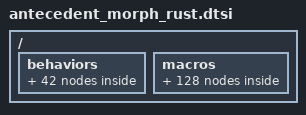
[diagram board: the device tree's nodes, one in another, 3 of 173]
// Rust schema version v1.2
// Automatically generated by Antecedent Morph Configurator

/ {
    behaviors {
        // Mod-Morphs
        // Base layer
        // NE
        amrsneagm: amrsneagm {
            compatible = "zmk,behavior-mod-morph";
            #binding-cells = <0>;
            bindings = <&amrsnea>, <&amrsneg>;
            mods = <(MOD_LGUI)>;
        };
        amrsnecagm: amrsnecagm {
            compatible = "zmk,behavior-mod-morph";
            #binding-cells = <0>;
            bindings = <&amrsnec>, <&amrsneagm>;
            mods = <(MOD_LALT|MOD_LGUI)>;
        };
        amrsnem: amrsnem {
            compatible = "zmk,behavior-mod-morph";
            #binding-cells = <0>;
            bindings = <&amrsne>, <&amrsnecagm>;
            mods = <(MOD_LCTL|MOD_LALT|MOD_LGUI)>;
        };
        // E
        amrseagm: amrseagm {
            compatible = "zmk,behavior-mod-morph";
            #binding-cells = <0>;
            bindings = <&amrsea>, <&amrseg>;
            mods = <(MOD_LGUI)>;
        };
        amrsecagm: amrsecagm {
            compatible = "zmk,behavior-mod-morph";
            #binding-cells = <0>;
            bindings = <&amrsec>, <&amrseagm>;
            mods = <(MOD_LALT|MOD_LGUI)>;
        };
        amrsem: amrsem {
            compatible = "zmk,behavior-mod-morph";
            #binding-cells = <0>;
            bindings = <&amrse>, <&amrsecagm>;
            mods = <(MOD_LCTL|MOD_LALT|MOD_LGUI)>;
        };
        // SE
        amrsseagm: amrsseagm {
            compatible = "zmk,behavior-mod-morph";
            #binding-cells = <0>;
            bindings = <&amrssea>, <&amrsseg>;
            mods = <(MOD_LGUI)>;
        };
        amrssecagm: amrssecagm {
            compatible = "zmk,behavior-mod-morph";
            #binding-cells = <0>;
            bindings = <&amrssec>, <&amrsseagm>;
            mods = <(MOD_LALT|MOD_LGUI)>;
        };
        amrssem: amrssem {
            compatible = "zmk,behavior-mod-morph";
            #binding-cells = <0>;
            bindings = <&amrsse>, <&amrssecagm>;
            mods = <(MOD_LCTL|MOD_LALT|MOD_LGUI)>;
        };
        // NW
        amrsnwagm: amrsnwagm {
            compatible = "zmk,behavior-mod-morph";
            #binding-cells = <0>;
            bindings = <&amrsnwa>, <&amrsnwg>;
            mods = <(MOD_RGUI)>;
        };
        amrsnwcagm: amrsnwcagm {
            compatible = "zmk,behavior-mod-morph";
            #binding-cells = <0>;
            bindings = <&amrsnwc>, <&amrsnwagm>;
            mods = <(MOD_RALT|MOD_RGUI)>;
        };
        amrsnwm: amrsnwm {
            compatible = "zmk,behavior-mod-morph";
            #binding-cells = <0>;
            bindings = <&amrsnw>, <&amrsnwcagm>;
            mods = <(MOD_RCTL|MOD_RALT|MOD_RGUI)>;
        };
        // W
        amrswagm: amrswagm {
            compatible = "zmk,behavior-mod-morph";
            #binding-cells = <0>;
            bindings = <&amrswa>, <&amrswg>;
            mods = <(MOD_RGUI)>;
        };
        amrswcagm: amrswcagm {
            compatible = "zmk,behavior-mod-morph";
            #binding-cells = <0>;
            bindings = <&amrswc>, <&amrswagm>;
            mods = <(MOD_RALT|MOD_RGUI)>;
        };
        amrswm: amrswm {
            compatible = "zmk,behavior-mod-morph";
            #binding-cells = <0>;
            bindings = <&amrsw>, <&amrswcagm>;
            mods = <(MOD_RCTL|MOD_RALT|MOD_RGUI)>;
        };
        // SW
        amrsswagm: amrsswagm {
            compatible = "zmk,behavior-mod-morph";
            #binding-cells = <0>;
            bindings = <&amrsswa>, <&amrsswg>;
            mods = <(MOD_RGUI)>;
        };
        amrsswcagm: amrsswcagm {
            compatible = "zmk,behavior-mod-morph";
            #binding-cells = <0>;
            bindings = <&amrsswc>, <&amrsswagm>;
            mods = <(MOD_RALT|MOD_RGUI)>;
        };
        amrsswm: amrsswm {
            compatible = "zmk,behavior-mod-morph";
            #binding-cells = <0>;
            bindings = <&amrssw>, <&amrsswcagm>;
            mods = <(MOD_RCTL|MOD_RALT|MOD_RGUI)>;
        };
        // Antecedent Morphs
        amrsne: am_rs_ne {
            compatible = "zmk,behavior-antecedent-morph";
            label = "AM_RS_NE";
            #binding-cells = <0>;
            defaults = <&none>;
            bindings = <&amrs_assert>, <&amrs_break>, <&amrs_crate>, <&amrs_enum>, <&amrs_for>, <&amrs_mod>, <&amrs_pub>, <&amrs_struct>, <&amrs_trait>, <&amrs_union>, <&amrs_while>, <&amrs_extern>, <&amrs_isok>, <&amrs_m1>, <&kp RBRC>, <&kp RPAR>, <&amrs_m7>, <&kp EQUAL>, <&amrs_from>, <&kp EQUAL>, <&kp EQUAL>, <&kp EQUAL>, <&kp EQUAL>, <&kp LBKT>, <&kp EQUAL>, <&kp EQUAL>, <&kp RBKT>, <&amrs_m11>, <&kp EQUAL>, <&amrs_m12>;
            antecedents = <A B C E F M P S T U W X DOT SQT LBRC LPAR RPAR STAR COLON PRCNT CARET PLUS EXCL HASH PIPE AMPS LBKT EQUAL MINUS SPACE>;
            max-delay-ms = <U_ANTMORPH_DELAY>;
        };
        amrsnec: am_rs_ne_c {
            compatible = "zmk,behavior-antecedent-morph";
            label = "AM_RS_NE_C";
            #binding-cells = <0>;
            defaults = <&none>;
            bindings = <&amrs_asserteq>, <&amrs_iserr>, <&amrs_m2>;
            antecedents = <A DOT SQT>;
            max-delay-ms = <U_ANTMORPH_DELAY>;
        };
        amrsnea: am_rs_ne_a {
            compatible = "zmk,behavior-antecedent-morph";
            label = "AM_RS_NE_A";
            #binding-cells = <0>;
            defaults = <&none>;
            bindings = <&amrs_assertne>;
            antecedents = <A>;
            max-delay-ms = <U_ANTMORPH_DELAY>;
        };
        amrsneg: am_rs_ne_g {
            compatible = "zmk,behavior-antecedent-morph";
            label = "AM_RS_NE_G";
            #binding-cells = <0>;
            defaults = <&none>;
            bindings = <&none>;
            antecedents = <0x070100>;
            max-delay-ms = <U_ANTMORPH_DELAY>;
        };
        amrse: am_rs_e {
            compatible = "zmk,behavior-antecedent-morph";
            label = "AM_RS_E";
            #binding-cells = <0>;
            defaults = <&none>;
            bindings = <&amrs_async>, <&amrs_bool>, <&amrs_const>, <&amrs_err>, <&amrs_f64>, <&amrs_impl>, <&amrs_move>, <&amrs_ptrnull>, <&amrs_ok>, <&amrs_pin>, <&amrs_return>, <&amrs_self>, <&amrs_type>, <&amrs_unsafe>, <&amrs_vec>, <&amrs_where>, <&kp UNDER>, <&amrs_unwrap>, <&kp SEMI>, <&kp SEMI>, <&amrs_m4>, <&kp SEMI>, <&amrs_self1>, <&kp SEMI>, <&amrs_mut2>, <&amrs_new>, <&kp LBKT>, <&amrs_derive>, <&amrs_mut3>, <&kp GT>, <&kp SEMI>, <&amrs_m9>, <&amrs_0>, <&kp GT>, <&amrs_mut4>;
            antecedents = <A B C E F I M N O P R S T U V W COMMA DOT SQT FSLH LBRC RBRC LPAR RPAR STAR COLON EXCL HASH AMPS UNDER RBKT SEMI EQUAL MINUS SPACE>;
            max-delay-ms = <U_ANTMORPH_DELAY>;
        };
        amrsec: am_rs_e_c {
            compatible = "zmk,behavior-antecedent-morph";
            label = "AM_RS_E_C";
            #binding-cells = <0>;
            defaults = <&none>;
            bindings = <&amrs_f32>, <&amrs_super>, <&amrs_unwrapor>, <&amrs_m5>, <&amrs_mut_self>, <&amrs_build>, <&amrs_00>, <&amrs_rust_v12>;
            antecedents = <F S DOT LBRC LPAR COLON EQUAL SPACE>;
            max-delay-ms = <U_ANTMORPH_DELAY>;
        };
        amrsea: am_rs_e_a {
            compatible = "zmk,behavior-antecedent-morph";
            label = "AM_RS_E_A";
            #binding-cells = <0>;
            defaults = <&none>;
            bindings = <&amrs_unwraporelse>;
            antecedents = <DOT>;
            max-delay-ms = <U_ANTMORPH_DELAY>;
        };
        amrseg: am_rs_e_g {
            compatible = "zmk,behavior-antecedent-morph";
            label = "AM_RS_E_G";
            #binding-cells = <0>;
            defaults = <&none>;
            bindings = <&none>;
            antecedents = <0x070100>;
            max-delay-ms = <U_ANTMORPH_DELAY>;
        };
        amrsse: am_rs_se {
            compatible = "zmk,behavior-antecedent-morph";
            label = "AM_RS_SE";
            #binding-cells = <0>;
            defaults = <&none>;
            bindings = <&amrs_dyn>, <&amrs_fn>, <&kp HASH>, <&amrs_static>, <&amrs_m>, <&amrs_expect>, <&amrs_m3>, <&amrs_m6>, <&amrs_move1>, <&amrs_m8>, <&amrs_right>, <&amrs_test>, <&amrs_dyn2>, <&amrs_m10>, <&amrs_as>;
            antecedents = <D F R S COMMA DOT SQT RBRC LPAR RPAR COLON HASH AMPS SEMI SPACE>;
            max-delay-ms = <U_ANTMORPH_DELAY>;
        };
        amrssec: am_rs_se_c {
            compatible = "zmk,behavior-antecedent-morph";
            label = "AM_RS_SE_C";
            #binding-cells = <0>;
            defaults = <&none>;
            bindings = <&amrs_shouldpanicexpe>;
            antecedents = <HASH>;
            max-delay-ms = <U_ANTMORPH_DELAY>;
        };
        amrssea: am_rs_se_a {
            compatible = "zmk,behavior-antecedent-morph";
            label = "AM_RS_SE_A";
            #binding-cells = <0>;
            defaults = <&none>;
            bindings = <&none>;
            antecedents = <0x070100>;
            max-delay-ms = <U_ANTMORPH_DELAY>;
        };
        amrsseg: am_rs_se_g {
            compatible = "zmk,behavior-antecedent-morph";
            label = "AM_RS_SE_G";
            #binding-cells = <0>;
            defaults = <&none>;
            bindings = <&none>;
            antecedents = <0x070100>;
            max-delay-ms = <U_ANTMORPH_DELAY>;
        };
        amrsnw: am_rs_nw {
            compatible = "zmk,behavior-antecedent-morph";
            label = "AM_RS_NW";
            #binding-cells = <0>;
            defaults = <&none>;
            bindings = <&amrs_dbg>, <&amrs_format>, <&amrs_char>, <&amrs_loop>, <&amrs_match>, <&amrs_none>, <&amrs_option>, <&amrs_println>, <&amrs_result>, <&amrs_some>, <&amrs_todo>, <&amrs_unimplemented>, <&kp EQUAL>, <&kp EQUAL>, <&amrs_static1>, <&kp EQUAL>, <&amrs_else_if>, <&kp LBKT>, <&kp RBKT>, <&kp LBKT>, <&kp LPAR>, <&kp RPAR>, <&amrs_in>;
            antecedents = <D F H L M N O P R S T U COMMA DOT SQT FSLH RBRC LPAR RPAR AMPS LBKT RBKT SPACE>;
            max-delay-ms = <U_ANTMORPH_DELAY>;
        };
        amrsnwc: am_rs_nw_c {
            compatible = "zmk,behavior-antecedent-morph";
            label = "AM_RS_NW_C";
            #binding-cells = <0>;
            defaults = <&none>;
            bindings = <&none>;
            antecedents = <0x070100>;
            max-delay-ms = <U_ANTMORPH_DELAY>;
        };
        amrsnwa: am_rs_nw_a {
            compatible = "zmk,behavior-antecedent-morph";
            label = "AM_RS_NW_A";
            #binding-cells = <0>;
            defaults = <&none>;
            bindings = <&none>;
            antecedents = <0x070100>;
            max-delay-ms = <U_ANTMORPH_DELAY>;
        };
        amrsnwg: am_rs_nw_g {
            compatible = "zmk,behavior-antecedent-morph";
            label = "AM_RS_NW_G";
            #binding-cells = <0>;
            defaults = <&none>;
            bindings = <&none>;
            antecedents = <0x070100>;
            max-delay-ms = <U_ANTMORPH_DELAY>;
        };
        amrsw: am_rs_w {
            compatible = "zmk,behavior-antecedent-morph";
            label = "AM_RS_W";
            #binding-cells = <0>;
            defaults = <&none>;
            bindings = <&amrs_continue>, <&amrs_else>, <&amrs_hashmap>, <&amrs_if>, <&amrs_let>, <&amrs_mut>, <&amrs_false>, <&amrs_other>, <&amrs_size>, <&amrs_tokio>, <&amrs_use>, <&amrs_true>, <&amrs_await>, <&kp RBRC>, <&amrs_else1>, <&amrs_mut1>, <&amrs__>, <&amrs_const1>, <&amrs_ignore>, <&amrs_raw>, <&kp GT>, <&kp EQUAL>;
            antecedents = <C E H I L M N O S T U Y DOT FSLH RBRC LPAR RPAR STAR HASH AMPS EQUAL SPACE>;
            max-delay-ms = <U_ANTMORPH_DELAY>;
        };
        amrswc: am_rs_w_c {
            compatible = "zmk,behavior-antecedent-morph";
            label = "AM_RS_W_C";
            #binding-cells = <0>;
            defaults = <&none>;
            bindings = <&amrs_let1>, <&amrs_use_std>, <&amrs_raw_const>;
            antecedents = <L U AMPS>;
            max-delay-ms = <U_ANTMORPH_DELAY>;
        };
        amrswa: am_rs_w_a {
            compatible = "zmk,behavior-antecedent-morph";
            label = "AM_RS_W_A";
            #binding-cells = <0>;
            defaults = <&none>;
            bindings = <&amrs_let2>, <&amrs_use_tokio>, <&amrs_raw_mut>;
            antecedents = <L U AMPS>;
            max-delay-ms = <U_ANTMORPH_DELAY>;
        };
        amrswg: am_rs_w_g {
            compatible = "zmk,behavior-antecedent-morph";
            label = "AM_RS_W_G";
            #binding-cells = <0>;
            defaults = <&none>;
            bindings = <&none>;
            antecedents = <0x070100>;
            max-delay-ms = <U_ANTMORPH_DELAY>;
        };
        amrssw: am_rs_sw {
            compatible = "zmk,behavior-antecedent-morph";
            label = "AM_RS_SW";
            #binding-cells = <0>;
            defaults = <&none>;
            bindings = <&amrs_duration>, <&amrs_either>, <&amrs_i64>, <&amrs_panic>, <&amrs_string>, <&amrs_u64>, <&amrs_dyn1>, <&amrs_next>, <&amrs_tostring>, <&amrs_left>, <&amrs_str>, <&amrs_dyn3>;
            antecedents = <D E I P S U COMMA DOT SQT COLON AMPS SPACE>;
            max-delay-ms = <U_ANTMORPH_DELAY>;
        };
        amrsswc: am_rs_sw_c {
            compatible = "zmk,behavior-antecedent-morph";
            label = "AM_RS_SW_C";
            #binding-cells = <0>;
            defaults = <&none>;
            bindings = <&amrs_i32>, <&amrs_u32>;
            antecedents = <I U>;
            max-delay-ms = <U_ANTMORPH_DELAY>;
        };
        amrsswa: am_rs_sw_a {
            compatible = "zmk,behavior-antecedent-morph";
            label = "AM_RS_SW_A";
            #binding-cells = <0>;
            defaults = <&none>;
            bindings = <&amrs_i16>, <&amrs_u16>;
            antecedents = <I U>;
            max-delay-ms = <U_ANTMORPH_DELAY>;
        };
        amrsswg: am_rs_sw_g {
            compatible = "zmk,behavior-antecedent-morph";
            label = "AM_RS_SW_G";
            #binding-cells = <0>;
            defaults = <&none>;
            bindings = <&none>;
            antecedents = <0x070100>;
            max-delay-ms = <U_ANTMORPH_DELAY>;
        };
    };
    macros {
        // 'A'
        amrs_assert: amrs_assert {
            compatible = "zmk,behavior-macro";
            #binding-cells = <0>;
            wait-ms = <U_ANTMORPH_MACRO_WAIT>;
            tap-ms = <U_ANTMORPH_MACRO_TAP>;
            // (a)ssert!(
            bindings = <&macro_tap &kp S &kp S &kp E &kp R &kp T &kp EXCL &kp LPAR>;
        };
        amrs_asserteq: amrs_asserteq {
            compatible = "zmk,behavior-macro";
            #binding-cells = <0>;
            wait-ms = <U_ANTMORPH_MACRO_WAIT>;
            tap-ms = <U_ANTMORPH_MACRO_TAP>;
            // (a)ssert_eq!(
            bindings = <&macro_release &kp LCTRL>, <&macro_tap &kp S &kp S &kp E &kp R &kp T &kp UNDER &kp E &kp Q &kp EXCL &kp LPAR>;
        };
        amrs_assertne: amrs_assertne {
            compatible = "zmk,behavior-macro";
            #binding-cells = <0>;
            wait-ms = <U_ANTMORPH_MACRO_WAIT>;
            tap-ms = <U_ANTMORPH_MACRO_TAP>;
            // (a)ssert_ne!(
            bindings = <&macro_release &kp LALT>, <&macro_tap &kp LALT>, <&macro_tap &kp S &kp S &kp E &kp R &kp T &kp UNDER &kp N &kp E &kp EXCL &kp LPAR>;
        };
        amrs_async: amrs_async {
            compatible = "zmk,behavior-macro";
            #binding-cells = <0>;
            wait-ms = <U_ANTMORPH_MACRO_WAIT>;
            tap-ms = <U_ANTMORPH_MACRO_TAP>;
            // (a)sync 
            bindings = <&macro_tap &kp S &kp Y &kp N &kp C &kp SPACE>;
        };
        // 'B'
        amrs_break: amrs_break {
            compatible = "zmk,behavior-macro";
            #binding-cells = <0>;
            wait-ms = <U_ANTMORPH_MACRO_WAIT>;
            tap-ms = <U_ANTMORPH_MACRO_TAP>;
            // (b)reak
            bindings = <&macro_tap &kp R &kp E &kp A &kp K>;
        };
        amrs_bool: amrs_bool {
            compatible = "zmk,behavior-macro";
            #binding-cells = <0>;
            wait-ms = <U_ANTMORPH_MACRO_WAIT>;
            tap-ms = <U_ANTMORPH_MACRO_TAP>;
            // (b)ool
            bindings = <&macro_tap &kp O &kp O &kp L>;
        };
        // 'C'
        amrs_crate: amrs_crate {
            compatible = "zmk,behavior-macro";
            #binding-cells = <0>;
            wait-ms = <U_ANTMORPH_MACRO_WAIT>;
            tap-ms = <U_ANTMORPH_MACRO_TAP>;
            // (c)rate
            bindings = <&macro_tap &kp R &kp A &kp T &kp E>;
        };
        amrs_const: amrs_const {
            compatible = "zmk,behavior-macro";
            #binding-cells = <0>;
            wait-ms = <U_ANTMORPH_MACRO_WAIT>;
            tap-ms = <U_ANTMORPH_MACRO_TAP>;
            // (c)onst
            bindings = <&macro_tap &kp O &kp N &kp S &kp T>;
        };
        amrs_continue: amrs_continue {
            compatible = "zmk,behavior-macro";
            #binding-cells = <0>;
            wait-ms = <U_ANTMORPH_MACRO_WAIT>;
            tap-ms = <U_ANTMORPH_MACRO_TAP>;
            // (c)ontinue
            bindings = <&macro_tap &kp O &kp N &kp T &kp I &kp N &kp U &kp E>;
        };
        // 'D'
        amrs_dyn: amrs_dyn {
            compatible = "zmk,behavior-macro";
            #binding-cells = <0>;
            wait-ms = <U_ANTMORPH_MACRO_WAIT>;
            tap-ms = <U_ANTMORPH_MACRO_TAP>;
            // (d)yn 
            bindings = <&macro_tap &kp Y &kp N &kp SPACE>;
        };
        amrs_dbg: amrs_dbg {
            compatible = "zmk,behavior-macro";
            #binding-cells = <0>;
            wait-ms = <U_ANTMORPH_MACRO_WAIT>;
            tap-ms = <U_ANTMORPH_MACRO_TAP>;
            // (d)bg!(
            bindings = <&macro_tap &kp B &kp G &kp EXCL &kp LPAR>;
        };
        amrs_duration: amrs_duration {
            compatible = "zmk,behavior-macro";
            #binding-cells = <0>;
            wait-ms = <U_ANTMORPH_MACRO_WAIT>;
            tap-ms = <U_ANTMORPH_MACRO_TAP>;
            // [d]Duration
            bindings = <&macro_tap &kp BSPC &kp LS(D) &kp U &kp R &kp A &kp T &kp I &kp O &kp N>;
        };
        // 'E'
        amrs_enum: amrs_enum {
            compatible = "zmk,behavior-macro";
            #binding-cells = <0>;
            wait-ms = <U_ANTMORPH_MACRO_WAIT>;
            tap-ms = <U_ANTMORPH_MACRO_TAP>;
            // (e)num 
            bindings = <&macro_tap &kp N &kp U &kp M &kp SPACE>;
        };
        amrs_err: amrs_err {
            compatible = "zmk,behavior-macro";
            #binding-cells = <0>;
            wait-ms = <U_ANTMORPH_MACRO_WAIT>;
            tap-ms = <U_ANTMORPH_MACRO_TAP>;
            // [e]Err(
            bindings = <&macro_tap &kp BSPC &kp LS(E) &kp R &kp R &kp LPAR>;
        };
        amrs_else: amrs_else {
            compatible = "zmk,behavior-macro";
            #binding-cells = <0>;
            wait-ms = <U_ANTMORPH_MACRO_WAIT>;
            tap-ms = <U_ANTMORPH_MACRO_TAP>;
            // (e)lse 
            bindings = <&macro_tap &kp L &kp S &kp E &kp SPACE>;
        };
        amrs_either: amrs_either {
            compatible = "zmk,behavior-macro";
            #binding-cells = <0>;
            wait-ms = <U_ANTMORPH_MACRO_WAIT>;
            tap-ms = <U_ANTMORPH_MACRO_TAP>;
            // [e]Either
            bindings = <&macro_tap &kp BSPC &kp LS(E) &kp I &kp T &kp H &kp E &kp R>;
        };
        // 'F'
        amrs_for: amrs_for {
            compatible = "zmk,behavior-macro";
            #binding-cells = <0>;
            wait-ms = <U_ANTMORPH_MACRO_WAIT>;
            tap-ms = <U_ANTMORPH_MACRO_TAP>;
            // (f)or 
            bindings = <&macro_tap &kp O &kp R &kp SPACE>;
        };
        amrs_f64: amrs_f64 {
            compatible = "zmk,behavior-macro";
            #binding-cells = <0>;
            wait-ms = <U_ANTMORPH_MACRO_WAIT>;
            tap-ms = <U_ANTMORPH_MACRO_TAP>;
            // (f)64
            bindings = <&macro_tap &kp N6 &kp N4>;
        };
        amrs_f32: amrs_f32 {
            compatible = "zmk,behavior-macro";
            #binding-cells = <0>;
            wait-ms = <U_ANTMORPH_MACRO_WAIT>;
            tap-ms = <U_ANTMORPH_MACRO_TAP>;
            // (f)32
            bindings = <&macro_release &kp LCTRL>, <&macro_tap &kp N3 &kp N2>;
        };
        amrs_fn: amrs_fn {
            compatible = "zmk,behavior-macro";
            #binding-cells = <0>;
            wait-ms = <U_ANTMORPH_MACRO_WAIT>;
            tap-ms = <U_ANTMORPH_MACRO_TAP>;
            // (f)n 
            bindings = <&macro_tap &kp N &kp SPACE>;
        };
        amrs_format: amrs_format {
            compatible = "zmk,behavior-macro";
            #binding-cells = <0>;
            wait-ms = <U_ANTMORPH_MACRO_WAIT>;
            tap-ms = <U_ANTMORPH_MACRO_TAP>;
            // (f)ormat!("
            bindings = <&macro_tap &kp O &kp R &kp M &kp A &kp T &kp EXCL &kp LPAR &kp DQT>;
        };
        // 'H'
        amrs_char: amrs_char {
            compatible = "zmk,behavior-macro";
            #binding-cells = <0>;
            wait-ms = <U_ANTMORPH_MACRO_WAIT>;
            tap-ms = <U_ANTMORPH_MACRO_TAP>;
            // [h]char
            bindings = <&macro_tap &kp BSPC &kp C &kp H &kp A &kp R>;
        };
        amrs_hashmap: amrs_hashmap {
            compatible = "zmk,behavior-macro";
            #binding-cells = <0>;
            wait-ms = <U_ANTMORPH_MACRO_WAIT>;
            tap-ms = <U_ANTMORPH_MACRO_TAP>;
            // [h]HashMap
            bindings = <&macro_tap &kp BSPC &kp LS(H) &kp A &kp S &kp H &kp LS(M) &kp A &kp P>;
        };
        // 'I'
        amrs_impl: amrs_impl {
            compatible = "zmk,behavior-macro";
            #binding-cells = <0>;
            wait-ms = <U_ANTMORPH_MACRO_WAIT>;
            tap-ms = <U_ANTMORPH_MACRO_TAP>;
            // (i)mpl
            bindings = <&macro_tap &kp M &kp P &kp L>;
        };
        amrs_if: amrs_if {
            compatible = "zmk,behavior-macro";
            #binding-cells = <0>;
            wait-ms = <U_ANTMORPH_MACRO_WAIT>;
            tap-ms = <U_ANTMORPH_MACRO_TAP>;
            // (i)f 
            bindings = <&macro_tap &kp F &kp SPACE>;
        };
        amrs_i64: amrs_i64 {
            compatible = "zmk,behavior-macro";
            #binding-cells = <0>;
            wait-ms = <U_ANTMORPH_MACRO_WAIT>;
            tap-ms = <U_ANTMORPH_MACRO_TAP>;
            // (i)64
            bindings = <&macro_tap &kp N6 &kp N4>;
        };
        amrs_i32: amrs_i32 {
            compatible = "zmk,behavior-macro";
            #binding-cells = <0>;
            wait-ms = <U_ANTMORPH_MACRO_WAIT>;
            tap-ms = <U_ANTMORPH_MACRO_TAP>;
            // (i)32
            bindings = <&macro_release &kp RCTRL>, <&macro_tap &kp N3 &kp N2>;
        };
        amrs_i16: amrs_i16 {
            compatible = "zmk,behavior-macro";
            #binding-cells = <0>;
            wait-ms = <U_ANTMORPH_MACRO_WAIT>;
            tap-ms = <U_ANTMORPH_MACRO_TAP>;
            // (i)16
            bindings = <&macro_release &kp RALT>, <&macro_tap &kp RALT>, <&macro_tap &kp N1 &kp N6>;
        };
        // 'L'
        amrs_loop: amrs_loop {
            compatible = "zmk,behavior-macro";
            #binding-cells = <0>;
            wait-ms = <U_ANTMORPH_MACRO_WAIT>;
            tap-ms = <U_ANTMORPH_MACRO_TAP>;
            // (l)oop {⏎
            bindings = <&macro_tap &kp O &kp O &kp P &kp SPACE &kp LBRC &kp RET>;
        };
        amrs_let: amrs_let {
            compatible = "zmk,behavior-macro";
            #binding-cells = <0>;
            wait-ms = <U_ANTMORPH_MACRO_WAIT>;
            tap-ms = <U_ANTMORPH_MACRO_TAP>;
            // (l)et 
            bindings = <&macro_tap &kp E &kp T &kp SPACE>;
        };
        amrs_let1: amrs_let1 {
            compatible = "zmk,behavior-macro";
            #binding-cells = <0>;
            wait-ms = <U_ANTMORPH_MACRO_WAIT>;
            tap-ms = <U_ANTMORPH_MACRO_TAP>;
            // (l)et (
            bindings = <&macro_release &kp RCTRL>, <&macro_tap &kp E &kp T &kp SPACE &kp LPAR>;
        };
        amrs_let2: amrs_let2 {
            compatible = "zmk,behavior-macro";
            #binding-cells = <0>;
            wait-ms = <U_ANTMORPH_MACRO_WAIT>;
            tap-ms = <U_ANTMORPH_MACRO_TAP>;
            // (l)et _ = 
            bindings = <&macro_release &kp RALT>, <&macro_tap &kp RALT>, <&macro_tap &kp E &kp T &kp SPACE &kp UNDER &kp SPACE &kp EQUAL &kp SPACE>;
        };
        // 'M'
        amrs_mod: amrs_mod {
            compatible = "zmk,behavior-macro";
            #binding-cells = <0>;
            wait-ms = <U_ANTMORPH_MACRO_WAIT>;
            tap-ms = <U_ANTMORPH_MACRO_TAP>;
            // (m)od 
            bindings = <&macro_tap &kp O &kp D &kp SPACE>;
        };
        amrs_move: amrs_move {
            compatible = "zmk,behavior-macro";
            #binding-cells = <0>;
            wait-ms = <U_ANTMORPH_MACRO_WAIT>;
            tap-ms = <U_ANTMORPH_MACRO_TAP>;
            // (m)ove 
            bindings = <&macro_tap &kp O &kp V &kp E &kp SPACE>;
        };
        amrs_match: amrs_match {
            compatible = "zmk,behavior-macro";
            #binding-cells = <0>;
            wait-ms = <U_ANTMORPH_MACRO_WAIT>;
            tap-ms = <U_ANTMORPH_MACRO_TAP>;
            // (m)atch 
            bindings = <&macro_tap &kp A &kp T &kp C &kp H &kp SPACE>;
        };
        amrs_mut: amrs_mut {
            compatible = "zmk,behavior-macro";
            #binding-cells = <0>;
            wait-ms = <U_ANTMORPH_MACRO_WAIT>;
            tap-ms = <U_ANTMORPH_MACRO_TAP>;
            // (m)ut 
            bindings = <&macro_tap &kp U &kp T &kp SPACE>;
        };
        // 'N'
        amrs_ptrnull: amrs_ptrnull {
            compatible = "zmk,behavior-macro";
            #binding-cells = <0>;
            wait-ms = <U_ANTMORPH_MACRO_WAIT>;
            tap-ms = <U_ANTMORPH_MACRO_TAP>;
            // [n]ptr::null()
            bindings = <&macro_tap &kp BSPC &kp P &kp T &kp R &kp COLON &kp COLON &kp N &kp U &kp L &kp L &kp LPAR &kp RPAR>;
        };
        amrs_none: amrs_none {
            compatible = "zmk,behavior-macro";
            #binding-cells = <0>;
            wait-ms = <U_ANTMORPH_MACRO_WAIT>;
            tap-ms = <U_ANTMORPH_MACRO_TAP>;
            // [n]None
            bindings = <&macro_tap &kp BSPC &kp LS(N) &kp O &kp N &kp E>;
        };
        amrs_false: amrs_false {
            compatible = "zmk,behavior-macro";
            #binding-cells = <0>;
            wait-ms = <U_ANTMORPH_MACRO_WAIT>;
            tap-ms = <U_ANTMORPH_MACRO_TAP>;
            // [n]false
            bindings = <&macro_tap &kp BSPC &kp F &kp A &kp L &kp S &kp E>;
        };
        // 'O'
        amrs_ok: amrs_ok {
            compatible = "zmk,behavior-macro";
            #binding-cells = <0>;
            wait-ms = <U_ANTMORPH_MACRO_WAIT>;
            tap-ms = <U_ANTMORPH_MACRO_TAP>;
            // [o]Ok(
            bindings = <&macro_tap &kp BSPC &kp LS(O) &kp K &kp LPAR>;
        };
        amrs_option: amrs_option {
            compatible = "zmk,behavior-macro";
            #binding-cells = <0>;
            wait-ms = <U_ANTMORPH_MACRO_WAIT>;
            tap-ms = <U_ANTMORPH_MACRO_TAP>;
            // [o]Option<
            bindings = <&macro_tap &kp BSPC &kp LS(O) &kp P &kp T &kp I &kp O &kp N &kp LT>;
        };
        amrs_other: amrs_other {
            compatible = "zmk,behavior-macro";
            #binding-cells = <0>;
            wait-ms = <U_ANTMORPH_MACRO_WAIT>;
            tap-ms = <U_ANTMORPH_MACRO_TAP>;
            // (o)ther
            bindings = <&macro_tap &kp T &kp H &kp E &kp R>;
        };
        // 'P'
        amrs_pub: amrs_pub {
            compatible = "zmk,behavior-macro";
            #binding-cells = <0>;
            wait-ms = <U_ANTMORPH_MACRO_WAIT>;
            tap-ms = <U_ANTMORPH_MACRO_TAP>;
            // (p)ub 
            bindings = <&macro_tap &kp U &kp B &kp SPACE>;
        };
        amrs_pin: amrs_pin {
            compatible = "zmk,behavior-macro";
            #binding-cells = <0>;
            wait-ms = <U_ANTMORPH_MACRO_WAIT>;
            tap-ms = <U_ANTMORPH_MACRO_TAP>;
            // (p)in!(
            bindings = <&macro_tap &kp I &kp N &kp EXCL &kp LPAR>;
        };
        amrs_println: amrs_println {
            compatible = "zmk,behavior-macro";
            #binding-cells = <0>;
            wait-ms = <U_ANTMORPH_MACRO_WAIT>;
            tap-ms = <U_ANTMORPH_MACRO_TAP>;
            // (p)rintln!("
            bindings = <&macro_tap &kp R &kp I &kp N &kp T &kp L &kp N &kp EXCL &kp LPAR &kp DQT>;
        };
        amrs_panic: amrs_panic {
            compatible = "zmk,behavior-macro";
            #binding-cells = <0>;
            wait-ms = <U_ANTMORPH_MACRO_WAIT>;
            tap-ms = <U_ANTMORPH_MACRO_TAP>;
            // (p)anic!("
            bindings = <&macro_tap &kp A &kp N &kp I &kp C &kp EXCL &kp LPAR &kp DQT>;
        };
        // 'R'
        amrs_return: amrs_return {
            compatible = "zmk,behavior-macro";
            #binding-cells = <0>;
            wait-ms = <U_ANTMORPH_MACRO_WAIT>;
            tap-ms = <U_ANTMORPH_MACRO_TAP>;
            // (r)eturn 
            bindings = <&macro_tap &kp E &kp T &kp U &kp R &kp N &kp SPACE>;
        };
        amrs_result: amrs_result {
            compatible = "zmk,behavior-macro";
            #binding-cells = <0>;
            wait-ms = <U_ANTMORPH_MACRO_WAIT>;
            tap-ms = <U_ANTMORPH_MACRO_TAP>;
            // [r]Result<
            bindings = <&macro_tap &kp BSPC &kp LS(R) &kp E &kp S &kp U &kp L &kp T &kp LT>;
        };
        // 'S'
        amrs_struct: amrs_struct {
            compatible = "zmk,behavior-macro";
            #binding-cells = <0>;
            wait-ms = <U_ANTMORPH_MACRO_WAIT>;
            tap-ms = <U_ANTMORPH_MACRO_TAP>;
            // (s)truct 
            bindings = <&macro_tap &kp T &kp R &kp U &kp C &kp T &kp SPACE>;
        };
        amrs_self: amrs_self {
            compatible = "zmk,behavior-macro";
            #binding-cells = <0>;
            wait-ms = <U_ANTMORPH_MACRO_WAIT>;
            tap-ms = <U_ANTMORPH_MACRO_TAP>;
            // (s)elf
            bindings = <&macro_tap &kp E &kp L &kp F>;
        };
        amrs_super: amrs_super {
            compatible = "zmk,behavior-macro";
            #binding-cells = <0>;
            wait-ms = <U_ANTMORPH_MACRO_WAIT>;
            tap-ms = <U_ANTMORPH_MACRO_TAP>;
            // (s)uper::
            bindings = <&macro_release &kp LCTRL>, <&macro_tap &kp U &kp P &kp E &kp R &kp COLON &kp COLON>;
        };
        amrs_static: amrs_static {
            compatible = "zmk,behavior-macro";
            #binding-cells = <0>;
            wait-ms = <U_ANTMORPH_MACRO_WAIT>;
            tap-ms = <U_ANTMORPH_MACRO_TAP>;
            // (s)tatic 
            bindings = <&macro_tap &kp T &kp A &kp T &kp I &kp C &kp SPACE>;
        };
        amrs_some: amrs_some {
            compatible = "zmk,behavior-macro";
            #binding-cells = <0>;
            wait-ms = <U_ANTMORPH_MACRO_WAIT>;
            tap-ms = <U_ANTMORPH_MACRO_TAP>;
            // [s]Some(
            bindings = <&macro_tap &kp BSPC &kp LS(S) &kp O &kp M &kp E &kp LPAR>;
        };
        amrs_size: amrs_size {
            compatible = "zmk,behavior-macro";
            #binding-cells = <0>;
            wait-ms = <U_ANTMORPH_MACRO_WAIT>;
            tap-ms = <U_ANTMORPH_MACRO_TAP>;
            // (s)ize
            bindings = <&macro_tap &kp I &kp Z &kp E>;
        };
        amrs_string: amrs_string {
            compatible = "zmk,behavior-macro";
            #binding-cells = <0>;
            wait-ms = <U_ANTMORPH_MACRO_WAIT>;
            tap-ms = <U_ANTMORPH_MACRO_TAP>;
            // [s]String
            bindings = <&macro_tap &kp BSPC &kp LS(S) &kp T &kp R &kp I &kp N &kp G>;
        };
        // 'T'
        amrs_trait: amrs_trait {
            compatible = "zmk,behavior-macro";
            #binding-cells = <0>;
            wait-ms = <U_ANTMORPH_MACRO_WAIT>;
            tap-ms = <U_ANTMORPH_MACRO_TAP>;
            // (t)rait 
            bindings = <&macro_tap &kp R &kp A &kp I &kp T &kp SPACE>;
        };
        amrs_type: amrs_type {
            compatible = "zmk,behavior-macro";
            #binding-cells = <0>;
            wait-ms = <U_ANTMORPH_MACRO_WAIT>;
            tap-ms = <U_ANTMORPH_MACRO_TAP>;
            // (t)ype 
            bindings = <&macro_tap &kp Y &kp P &kp E &kp SPACE>;
        };
        amrs_todo: amrs_todo {
            compatible = "zmk,behavior-macro";
            #binding-cells = <0>;
            wait-ms = <U_ANTMORPH_MACRO_WAIT>;
            tap-ms = <U_ANTMORPH_MACRO_TAP>;
            // (t)odo!(
            bindings = <&macro_tap &kp O &kp D &kp O &kp EXCL &kp LPAR>;
        };
        amrs_tokio: amrs_tokio {
            compatible = "zmk,behavior-macro";
            #binding-cells = <0>;
            wait-ms = <U_ANTMORPH_MACRO_WAIT>;
            tap-ms = <U_ANTMORPH_MACRO_TAP>;
            // (t)okio
            bindings = <&macro_tap &kp O &kp K &kp I &kp O>;
        };
        // 'U'
        amrs_union: amrs_union {
            compatible = "zmk,behavior-macro";
            #binding-cells = <0>;
            wait-ms = <U_ANTMORPH_MACRO_WAIT>;
            tap-ms = <U_ANTMORPH_MACRO_TAP>;
            // (u)nion 
            bindings = <&macro_tap &kp N &kp I &kp O &kp N &kp SPACE>;
        };
        amrs_unsafe: amrs_unsafe {
            compatible = "zmk,behavior-macro";
            #binding-cells = <0>;
            wait-ms = <U_ANTMORPH_MACRO_WAIT>;
            tap-ms = <U_ANTMORPH_MACRO_TAP>;
            // (u)nsafe 
            bindings = <&macro_tap &kp N &kp S &kp A &kp F &kp E &kp SPACE>;
        };
        amrs_unimplemented: amrs_unimplemented {
            compatible = "zmk,behavior-macro";
            #binding-cells = <0>;
            wait-ms = <U_ANTMORPH_MACRO_WAIT>;
            tap-ms = <U_ANTMORPH_MACRO_TAP>;
            // (u)nimplemented!()
            bindings = <&macro_tap &kp N &kp I &kp M &kp P &kp L &kp E &kp M &kp E &kp N &kp T &kp E &kp D &kp EXCL &kp LPAR &kp RPAR>;
        };
        amrs_use: amrs_use {
            compatible = "zmk,behavior-macro";
            #binding-cells = <0>;
            wait-ms = <U_ANTMORPH_MACRO_WAIT>;
            tap-ms = <U_ANTMORPH_MACRO_TAP>;
            // (u)se 
            bindings = <&macro_tap &kp S &kp E &kp SPACE>;
        };
        amrs_use_std: amrs_use_std {
            compatible = "zmk,behavior-macro";
            #binding-cells = <0>;
            wait-ms = <U_ANTMORPH_MACRO_WAIT>;
            tap-ms = <U_ANTMORPH_MACRO_TAP>;
            // (u)se std::
            bindings = <&macro_release &kp RCTRL>, <&macro_tap &kp S &kp E &kp SPACE &kp S &kp T &kp D &kp COLON &kp COLON>;
        };
        amrs_use_tokio: amrs_use_tokio {
            compatible = "zmk,behavior-macro";
            #binding-cells = <0>;
            wait-ms = <U_ANTMORPH_MACRO_WAIT>;
            tap-ms = <U_ANTMORPH_MACRO_TAP>;
            // (u)se tokio::
            bindings = <&macro_release &kp RALT>, <&macro_tap &kp RALT>, <&macro_tap &kp S &kp E &kp SPACE &kp T &kp O &kp K &kp I &kp O &kp COLON &kp COLON>;
        };
        amrs_u64: amrs_u64 {
            compatible = "zmk,behavior-macro";
            #binding-cells = <0>;
            wait-ms = <U_ANTMORPH_MACRO_WAIT>;
            tap-ms = <U_ANTMORPH_MACRO_TAP>;
            // (u)64
            bindings = <&macro_tap &kp N6 &kp N4>;
        };
        amrs_u32: amrs_u32 {
            compatible = "zmk,behavior-macro";
            #binding-cells = <0>;
            wait-ms = <U_ANTMORPH_MACRO_WAIT>;
            tap-ms = <U_ANTMORPH_MACRO_TAP>;
            // (u)32
            bindings = <&macro_release &kp RCTRL>, <&macro_tap &kp N3 &kp N2>;
        };
        amrs_u16: amrs_u16 {
            compatible = "zmk,behavior-macro";
            #binding-cells = <0>;
            wait-ms = <U_ANTMORPH_MACRO_WAIT>;
            tap-ms = <U_ANTMORPH_MACRO_TAP>;
            // (u)16
            bindings = <&macro_release &kp RALT>, <&macro_tap &kp RALT>, <&macro_tap &kp N1 &kp N6>;
        };
        // 'V'
        amrs_vec: amrs_vec {
            compatible = "zmk,behavior-macro";
            #binding-cells = <0>;
            wait-ms = <U_ANTMORPH_MACRO_WAIT>;
            tap-ms = <U_ANTMORPH_MACRO_TAP>;
            // (v)ec![
            bindings = <&macro_tap &kp E &kp C &kp EXCL &kp LBKT>;
        };
        // 'W'
        amrs_while: amrs_while {
            compatible = "zmk,behavior-macro";
            #binding-cells = <0>;
            wait-ms = <U_ANTMORPH_MACRO_WAIT>;
            tap-ms = <U_ANTMORPH_MACRO_TAP>;
            // (w)hile 
            bindings = <&macro_tap &kp H &kp I &kp L &kp E &kp SPACE>;
        };
        amrs_where: amrs_where {
            compatible = "zmk,behavior-macro";
            #binding-cells = <0>;
            wait-ms = <U_ANTMORPH_MACRO_WAIT>;
            tap-ms = <U_ANTMORPH_MACRO_TAP>;
            // (w)here
            bindings = <&macro_tap &kp H &kp E &kp R &kp E>;
        };
        // 'X'
        amrs_extern: amrs_extern {
            compatible = "zmk,behavior-macro";
            #binding-cells = <0>;
            wait-ms = <U_ANTMORPH_MACRO_WAIT>;
            tap-ms = <U_ANTMORPH_MACRO_TAP>;
            // [x]extern 
            bindings = <&macro_tap &kp BSPC &kp E &kp X &kp T &kp E &kp R &kp N &kp SPACE>;
        };
        // 'Y'
        amrs_true: amrs_true {
            compatible = "zmk,behavior-macro";
            #binding-cells = <0>;
            wait-ms = <U_ANTMORPH_MACRO_WAIT>;
            tap-ms = <U_ANTMORPH_MACRO_TAP>;
            // [y]true
            bindings = <&macro_tap &kp BSPC &kp T &kp R &kp U &kp E>;
        };
        // ','
        amrs_m: amrs_m {
            compatible = "zmk,behavior-macro";
            #binding-cells = <0>;
            wait-ms = <U_ANTMORPH_MACRO_WAIT>;
            tap-ms = <U_ANTMORPH_MACRO_TAP>;
            // (,)⏎}
            bindings = <&macro_tap &kp RET &kp RBRC>;
        };
        amrs_dyn1: amrs_dyn1 {
            compatible = "zmk,behavior-macro";
            #binding-cells = <0>;
            wait-ms = <U_ANTMORPH_MACRO_WAIT>;
            tap-ms = <U_ANTMORPH_MACRO_TAP>;
            // (,)dyn 
            bindings = <&macro_tap &kp D &kp Y &kp N &kp SPACE>;
        };
        // '.'
        amrs_isok: amrs_isok {
            compatible = "zmk,behavior-macro";
            #binding-cells = <0>;
            wait-ms = <U_ANTMORPH_MACRO_WAIT>;
            tap-ms = <U_ANTMORPH_MACRO_TAP>;
            // (.)is_ok()
            bindings = <&macro_tap &kp I &kp S &kp UNDER &kp O &kp K &kp LPAR &kp RPAR>;
        };
        amrs_iserr: amrs_iserr {
            compatible = "zmk,behavior-macro";
            #binding-cells = <0>;
            wait-ms = <U_ANTMORPH_MACRO_WAIT>;
            tap-ms = <U_ANTMORPH_MACRO_TAP>;
            // (.)is_err()
            bindings = <&macro_release &kp LCTRL>, <&macro_tap &kp I &kp S &kp UNDER &kp E &kp R &kp R &kp LPAR &kp RPAR>;
        };
        amrs_unwrap: amrs_unwrap {
            compatible = "zmk,behavior-macro";
            #binding-cells = <0>;
            wait-ms = <U_ANTMORPH_MACRO_WAIT>;
            tap-ms = <U_ANTMORPH_MACRO_TAP>;
            // (.)unwrap()
            bindings = <&macro_tap &kp U &kp N &kp W &kp R &kp A &kp P &kp LPAR &kp RPAR>;
        };
        amrs_unwrapor: amrs_unwrapor {
            compatible = "zmk,behavior-macro";
            #binding-cells = <0>;
            wait-ms = <U_ANTMORPH_MACRO_WAIT>;
            tap-ms = <U_ANTMORPH_MACRO_TAP>;
            // (.)unwrap_or(
            bindings = <&macro_release &kp LCTRL>, <&macro_tap &kp U &kp N &kp W &kp R &kp A &kp P &kp UNDER &kp O &kp R &kp LPAR>;
        };
        amrs_unwraporelse: amrs_unwraporelse {
            compatible = "zmk,behavior-macro";
            #binding-cells = <0>;
            wait-ms = <U_ANTMORPH_MACRO_WAIT>;
            tap-ms = <U_ANTMORPH_MACRO_TAP>;
            // (.)unwrap_or_else(
            bindings = <&macro_release &kp LALT>, <&macro_tap &kp LALT>, <&macro_tap &kp U &kp N &kp W &kp R &kp A &kp P &kp UNDER &kp O &kp R &kp UNDER &kp E &kp L &kp S &kp E &kp LPAR>;
        };
        amrs_expect: amrs_expect {
            compatible = "zmk,behavior-macro";
            #binding-cells = <0>;
            wait-ms = <U_ANTMORPH_MACRO_WAIT>;
            tap-ms = <U_ANTMORPH_MACRO_TAP>;
            // (.)expect("
            bindings = <&macro_tap &kp E &kp X &kp P &kp E &kp C &kp T &kp LPAR &kp DQT>;
        };
        amrs_await: amrs_await {
            compatible = "zmk,behavior-macro";
            #binding-cells = <0>;
            wait-ms = <U_ANTMORPH_MACRO_WAIT>;
            tap-ms = <U_ANTMORPH_MACRO_TAP>;
            // (.)await
            bindings = <&macro_tap &kp A &kp W &kp A &kp I &kp T>;
        };
        amrs_next: amrs_next {
            compatible = "zmk,behavior-macro";
            #binding-cells = <0>;
            wait-ms = <U_ANTMORPH_MACRO_WAIT>;
            tap-ms = <U_ANTMORPH_MACRO_TAP>;
            // (.)next()
            bindings = <&macro_tap &kp N &kp E &kp X &kp T &kp LPAR &kp RPAR>;
        };
        // '''
        amrs_m1: amrs_m1 {
            compatible = "zmk,behavior-macro";
            #binding-cells = <0>;
            wait-ms = <U_ANTMORPH_MACRO_WAIT>;
            tap-ms = <U_ANTMORPH_MACRO_TAP>;
            // ('), "
            bindings = <&macro_tap &kp COMMA &kp SPACE &kp DQT>;
        };
        amrs_m2: amrs_m2 {
            compatible = "zmk,behavior-macro";
            #binding-cells = <0>;
            wait-ms = <U_ANTMORPH_MACRO_WAIT>;
            tap-ms = <U_ANTMORPH_MACRO_TAP>;
            // ('),⏎"
            bindings = <&macro_release &kp LCTRL>, <&macro_tap &kp COMMA &kp RET &kp DQT>;
        };
        amrs_m3: amrs_m3 {
            compatible = "zmk,behavior-macro";
            #binding-cells = <0>;
            wait-ms = <U_ANTMORPH_MACRO_WAIT>;
            tap-ms = <U_ANTMORPH_MACRO_TAP>;
            // (')⏎}
            bindings = <&macro_tap &kp RET &kp RBRC>;
        };
        amrs_static1: amrs_static1 {
            compatible = "zmk,behavior-macro";
            #binding-cells = <0>;
            wait-ms = <U_ANTMORPH_MACRO_WAIT>;
            tap-ms = <U_ANTMORPH_MACRO_TAP>;
            // (')static
            bindings = <&macro_tap &kp S &kp T &kp A &kp T &kp I &kp C>;
        };
        amrs_tostring: amrs_tostring {
            compatible = "zmk,behavior-macro";
            #binding-cells = <0>;
            wait-ms = <U_ANTMORPH_MACRO_WAIT>;
            tap-ms = <U_ANTMORPH_MACRO_TAP>;
            // (').to_string()
            bindings = <&macro_tap &kp DOT &kp T &kp O &kp UNDER &kp S &kp T &kp R &kp I &kp N &kp G &kp LPAR &kp RPAR>;
        };
        // '{'
        amrs_m4: amrs_m4 {
            compatible = "zmk,behavior-macro";
            #binding-cells = <0>;
            wait-ms = <U_ANTMORPH_MACRO_WAIT>;
            tap-ms = <U_ANTMORPH_MACRO_TAP>;
            // ({):?}
            bindings = <&macro_tap &kp COLON &kp QMARK &kp RBRC>;
        };
        amrs_m5: amrs_m5 {
            compatible = "zmk,behavior-macro";
            #binding-cells = <0>;
            wait-ms = <U_ANTMORPH_MACRO_WAIT>;
            tap-ms = <U_ANTMORPH_MACRO_TAP>;
            // ({):#?}
            bindings = <&macro_release &kp LCTRL>, <&macro_tap &kp COLON &kp HASH &kp QMARK &kp RBRC>;
        };
        // '}'
        amrs_m6: amrs_m6 {
            compatible = "zmk,behavior-macro";
            #binding-cells = <0>;
            wait-ms = <U_ANTMORPH_MACRO_WAIT>;
            tap-ms = <U_ANTMORPH_MACRO_TAP>;
            // (})⏎}
            bindings = <&macro_tap &kp RET &kp RBRC>;
        };
        amrs_else_if: amrs_else_if {
            compatible = "zmk,behavior-macro";
            #binding-cells = <0>;
            wait-ms = <U_ANTMORPH_MACRO_WAIT>;
            tap-ms = <U_ANTMORPH_MACRO_TAP>;
            // (}) else if 
            bindings = <&macro_tap &kp SPACE &kp E &kp L &kp S &kp E &kp SPACE &kp I &kp F &kp SPACE>;
        };
        amrs_else1: amrs_else1 {
            compatible = "zmk,behavior-macro";
            #binding-cells = <0>;
            wait-ms = <U_ANTMORPH_MACRO_WAIT>;
            tap-ms = <U_ANTMORPH_MACRO_TAP>;
            // (}) else {
            bindings = <&macro_tap &kp SPACE &kp E &kp L &kp S &kp E &kp SPACE &kp LBRC>;
        };
        // '('
        amrs_self1: amrs_self1 {
            compatible = "zmk,behavior-macro";
            #binding-cells = <0>;
            wait-ms = <U_ANTMORPH_MACRO_WAIT>;
            tap-ms = <U_ANTMORPH_MACRO_TAP>;
            // (()&self
            bindings = <&macro_tap &kp AMPS &kp S &kp E &kp L &kp F>;
        };
        amrs_mut_self: amrs_mut_self {
            compatible = "zmk,behavior-macro";
            #binding-cells = <0>;
            wait-ms = <U_ANTMORPH_MACRO_WAIT>;
            tap-ms = <U_ANTMORPH_MACRO_TAP>;
            // (()&mut self
            bindings = <&macro_release &kp LCTRL>, <&macro_tap &kp AMPS &kp M &kp U &kp T &kp SPACE &kp S &kp E &kp L &kp F>;
        };
        amrs_move1: amrs_move1 {
            compatible = "zmk,behavior-macro";
            #binding-cells = <0>;
            wait-ms = <U_ANTMORPH_MACRO_WAIT>;
            tap-ms = <U_ANTMORPH_MACRO_TAP>;
            // (()move || 
            bindings = <&macro_tap &kp M &kp O &kp V &kp E &kp SPACE &kp PIPE &kp PIPE &kp SPACE>;
        };
        amrs_mut1: amrs_mut1 {
            compatible = "zmk,behavior-macro";
            #binding-cells = <0>;
            wait-ms = <U_ANTMORPH_MACRO_WAIT>;
            tap-ms = <U_ANTMORPH_MACRO_TAP>;
            // (()mut 
            bindings = <&macro_tap &kp M &kp U &kp T &kp SPACE>;
        };
        // ')'
        amrs_m7: amrs_m7 {
            compatible = "zmk,behavior-macro";
            #binding-cells = <0>;
            wait-ms = <U_ANTMORPH_MACRO_WAIT>;
            tap-ms = <U_ANTMORPH_MACRO_TAP>;
            // ()) {⏎
            bindings = <&macro_tap &kp SPACE &kp LBRC &kp RET>;
        };
        amrs_m8: amrs_m8 {
            compatible = "zmk,behavior-macro";
            #binding-cells = <0>;
            wait-ms = <U_ANTMORPH_MACRO_WAIT>;
            tap-ms = <U_ANTMORPH_MACRO_TAP>;
            // ())⏎}
            bindings = <&macro_tap &kp RET &kp RBRC>;
        };
        amrs__: amrs__ {
            compatible = "zmk,behavior-macro";
            #binding-cells = <0>;
            wait-ms = <U_ANTMORPH_MACRO_WAIT>;
            tap-ms = <U_ANTMORPH_MACRO_TAP>;
            // ()) -> 
            bindings = <&macro_tap &kp SPACE &kp MINUS &kp GT &kp SPACE>;
        };
        // '*'
        amrs_mut2: amrs_mut2 {
            compatible = "zmk,behavior-macro";
            #binding-cells = <0>;
            wait-ms = <U_ANTMORPH_MACRO_WAIT>;
            tap-ms = <U_ANTMORPH_MACRO_TAP>;
            // (*)mut 
            bindings = <&macro_tap &kp M &kp U &kp T &kp SPACE>;
        };
        amrs_const1: amrs_const1 {
            compatible = "zmk,behavior-macro";
            #binding-cells = <0>;
            wait-ms = <U_ANTMORPH_MACRO_WAIT>;
            tap-ms = <U_ANTMORPH_MACRO_TAP>;
            // (*)const 
            bindings = <&macro_tap &kp C &kp O &kp N &kp S &kp T &kp SPACE>;
        };
        // ':'
        amrs_from: amrs_from {
            compatible = "zmk,behavior-macro";
            #binding-cells = <0>;
            wait-ms = <U_ANTMORPH_MACRO_WAIT>;
            tap-ms = <U_ANTMORPH_MACRO_TAP>;
            // (:)from(
            bindings = <&macro_tap &kp F &kp R &kp O &kp M &kp LPAR>;
        };
        amrs_new: amrs_new {
            compatible = "zmk,behavior-macro";
            #binding-cells = <0>;
            wait-ms = <U_ANTMORPH_MACRO_WAIT>;
            tap-ms = <U_ANTMORPH_MACRO_TAP>;
            // (:)new(
            bindings = <&macro_tap &kp N &kp E &kp W &kp LPAR>;
        };
        amrs_build: amrs_build {
            compatible = "zmk,behavior-macro";
            #binding-cells = <0>;
            wait-ms = <U_ANTMORPH_MACRO_WAIT>;
            tap-ms = <U_ANTMORPH_MACRO_TAP>;
            // (:)build(
            bindings = <&macro_release &kp LCTRL>, <&macro_tap &kp B &kp U &kp I &kp L &kp D &kp LPAR>;
        };
        amrs_right: amrs_right {
            compatible = "zmk,behavior-macro";
            #binding-cells = <0>;
            wait-ms = <U_ANTMORPH_MACRO_WAIT>;
            tap-ms = <U_ANTMORPH_MACRO_TAP>;
            // (:)Right(
            bindings = <&macro_tap &kp LS(R) &kp I &kp G &kp H &kp T &kp LPAR>;
        };
        amrs_left: amrs_left {
            compatible = "zmk,behavior-macro";
            #binding-cells = <0>;
            wait-ms = <U_ANTMORPH_MACRO_WAIT>;
            tap-ms = <U_ANTMORPH_MACRO_TAP>;
            // (:)Left(
            bindings = <&macro_tap &kp LS(L) &kp E &kp F &kp T &kp LPAR>;
        };
        // '#'
        amrs_derive: amrs_derive {
            compatible = "zmk,behavior-macro";
            #binding-cells = <0>;
            wait-ms = <U_ANTMORPH_MACRO_WAIT>;
            tap-ms = <U_ANTMORPH_MACRO_TAP>;
            // (#)[derive(
            bindings = <&macro_tap &kp LBKT &kp D &kp E &kp R &kp I &kp V &kp E &kp LPAR>;
        };
        amrs_test: amrs_test {
            compatible = "zmk,behavior-macro";
            #binding-cells = <0>;
            wait-ms = <U_ANTMORPH_MACRO_WAIT>;
            tap-ms = <U_ANTMORPH_MACRO_TAP>;
            // (#)[test]
            bindings = <&macro_tap &kp LBKT &kp T &kp E &kp S &kp T &kp RBKT>;
        };
        amrs_shouldpanicexpe: amrs_shouldpanicexpe {
            compatible = "zmk,behavior-macro";
            #binding-cells = <0>;
            wait-ms = <U_ANTMORPH_MACRO_WAIT>;
            tap-ms = <U_ANTMORPH_MACRO_TAP>;
            // (#)[should_panic(expected = "
            bindings = <&macro_release &kp LCTRL>, <&macro_tap &kp LBKT &kp S &kp H &kp O &kp U &kp L &kp D &kp UNDER &kp P &kp A &kp N &kp I &kp C &kp LPAR &kp E &kp X &kp P &kp E &kp C &kp T &kp E &kp D &kp SPACE &kp EQUAL &kp SPACE &kp DQT>;
        };
        amrs_ignore: amrs_ignore {
            compatible = "zmk,behavior-macro";
            #binding-cells = <0>;
            wait-ms = <U_ANTMORPH_MACRO_WAIT>;
            tap-ms = <U_ANTMORPH_MACRO_TAP>;
            // (#)[ignore]
            bindings = <&macro_tap &kp LBKT &kp I &kp G &kp N &kp O &kp R &kp E &kp RBKT>;
        };
        // '&'
        amrs_mut3: amrs_mut3 {
            compatible = "zmk,behavior-macro";
            #binding-cells = <0>;
            wait-ms = <U_ANTMORPH_MACRO_WAIT>;
            tap-ms = <U_ANTMORPH_MACRO_TAP>;
            // (&)mut 
            bindings = <&macro_tap &kp M &kp U &kp T &kp SPACE>;
        };
        amrs_dyn2: amrs_dyn2 {
            compatible = "zmk,behavior-macro";
            #binding-cells = <0>;
            wait-ms = <U_ANTMORPH_MACRO_WAIT>;
            tap-ms = <U_ANTMORPH_MACRO_TAP>;
            // (&)dyn 
            bindings = <&macro_tap &kp D &kp Y &kp N &kp SPACE>;
        };
        amrs_raw: amrs_raw {
            compatible = "zmk,behavior-macro";
            #binding-cells = <0>;
            wait-ms = <U_ANTMORPH_MACRO_WAIT>;
            tap-ms = <U_ANTMORPH_MACRO_TAP>;
            // (&)raw 
            bindings = <&macro_tap &kp R &kp A &kp W &kp SPACE>;
        };
        amrs_raw_const: amrs_raw_const {
            compatible = "zmk,behavior-macro";
            #binding-cells = <0>;
            wait-ms = <U_ANTMORPH_MACRO_WAIT>;
            tap-ms = <U_ANTMORPH_MACRO_TAP>;
            // (&)raw const 
            bindings = <&macro_release &kp RCTRL>, <&macro_tap &kp R &kp A &kp W &kp SPACE &kp C &kp O &kp N &kp S &kp T &kp SPACE>;
        };
        amrs_raw_mut: amrs_raw_mut {
            compatible = "zmk,behavior-macro";
            #binding-cells = <0>;
            wait-ms = <U_ANTMORPH_MACRO_WAIT>;
            tap-ms = <U_ANTMORPH_MACRO_TAP>;
            // (&)raw mut 
            bindings = <&macro_release &kp RALT>, <&macro_tap &kp RALT>, <&macro_tap &kp R &kp A &kp W &kp SPACE &kp M &kp U &kp T &kp SPACE>;
        };
        amrs_str: amrs_str {
            compatible = "zmk,behavior-macro";
            #binding-cells = <0>;
            wait-ms = <U_ANTMORPH_MACRO_WAIT>;
            tap-ms = <U_ANTMORPH_MACRO_TAP>;
            // (&)str
            bindings = <&macro_tap &kp S &kp T &kp R>;
        };
        // ';'
        amrs_m9: amrs_m9 {
            compatible = "zmk,behavior-macro";
            #binding-cells = <0>;
            wait-ms = <U_ANTMORPH_MACRO_WAIT>;
            tap-ms = <U_ANTMORPH_MACRO_TAP>;
            // (;)⏎}
            bindings = <&macro_tap &kp RET &kp RBRC>;
        };
        amrs_m10: amrs_m10 {
            compatible = "zmk,behavior-macro";
            #binding-cells = <0>;
            wait-ms = <U_ANTMORPH_MACRO_WAIT>;
            tap-ms = <U_ANTMORPH_MACRO_TAP>;
            // (;)⏎}⏎
            bindings = <&macro_tap &kp RET &kp RBRC &kp RET>;
        };
        // '='
        amrs_m11: amrs_m11 {
            compatible = "zmk,behavior-macro";
            #binding-cells = <0>;
            wait-ms = <U_ANTMORPH_MACRO_WAIT>;
            tap-ms = <U_ANTMORPH_MACRO_TAP>;
            // (=) [
            bindings = <&macro_tap &kp SPACE &kp LBKT>;
        };
        amrs_0: amrs_0 {
            compatible = "zmk,behavior-macro";
            #binding-cells = <0>;
            wait-ms = <U_ANTMORPH_MACRO_WAIT>;
            tap-ms = <U_ANTMORPH_MACRO_TAP>;
            // (=) 0;
            bindings = <&macro_tap &kp SPACE &kp N0 &kp SEMI>;
        };
        amrs_00: amrs_00 {
            compatible = "zmk,behavior-macro";
            #binding-cells = <0>;
            wait-ms = <U_ANTMORPH_MACRO_WAIT>;
            tap-ms = <U_ANTMORPH_MACRO_TAP>;
            // (=) 0.0;
            bindings = <&macro_release &kp LCTRL>, <&macro_tap &kp SPACE &kp N0 &kp DOT &kp N0 &kp SEMI>;
        };
        // ' '
        amrs_m12: amrs_m12 {
            compatible = "zmk,behavior-macro";
            #binding-cells = <0>;
            wait-ms = <U_ANTMORPH_MACRO_WAIT>;
            tap-ms = <U_ANTMORPH_MACRO_TAP>;
            // ( ){⏎
            bindings = <&macro_tap &kp LBRC &kp RET>;
        };
        amrs_mut4: amrs_mut4 {
            compatible = "zmk,behavior-macro";
            #binding-cells = <0>;
            wait-ms = <U_ANTMORPH_MACRO_WAIT>;
            tap-ms = <U_ANTMORPH_MACRO_TAP>;
            // ( )mut 
            bindings = <&macro_tap &kp M &kp U &kp T &kp SPACE>;
        };
        amrs_rust_v12: amrs_rust_v12 {
            compatible = "zmk,behavior-macro";
            #binding-cells = <0>;
            wait-ms = <U_ANTMORPH_MACRO_WAIT>;
            tap-ms = <U_ANTMORPH_MACRO_TAP>;
            // [ ]Rust v1.2
            bindings = <&macro_release &kp LCTRL>, <&macro_tap &kp BSPC &kp LS(R) &kp U &kp S &kp T &kp SPACE &kp V &kp N1 &kp DOT &kp N2>;
        };
        amrs_as: amrs_as {
            compatible = "zmk,behavior-macro";
            #binding-cells = <0>;
            wait-ms = <U_ANTMORPH_MACRO_WAIT>;
            tap-ms = <U_ANTMORPH_MACRO_TAP>;
            // ( )as 
            bindings = <&macro_tap &kp A &kp S &kp SPACE>;
        };
        amrs_in: amrs_in {
            compatible = "zmk,behavior-macro";
            #binding-cells = <0>;
            wait-ms = <U_ANTMORPH_MACRO_WAIT>;
            tap-ms = <U_ANTMORPH_MACRO_TAP>;
            // ( )in 
            bindings = <&macro_tap &kp I &kp N &kp SPACE>;
        };
        amrs_dyn3: amrs_dyn3 {
            compatible = "zmk,behavior-macro";
            #binding-cells = <0>;
            wait-ms = <U_ANTMORPH_MACRO_WAIT>;
            tap-ms = <U_ANTMORPH_MACRO_TAP>;
            // ( )dyn 
            bindings = <&macro_tap &kp D &kp Y &kp N &kp SPACE>;
        };
    };
};
